# HK32F0301MxxC register map
Vendor: HKMicroChip Ltd.; Series: HK32F0301MxxC; File version: 0.9
CPU: CM0 r0p0, little endian, no MPU, no FPU, 3 interrupt priority bits
Registers are 32-bit, read-write, reset 0x0 unless marked. A register's access mark holds for its fields unless they carry their own. Offsets are from the block's base; [hi:lo] are bit positions; {n}, {i} and the like mark numbered series.

## TIM2
Base 0x40000000
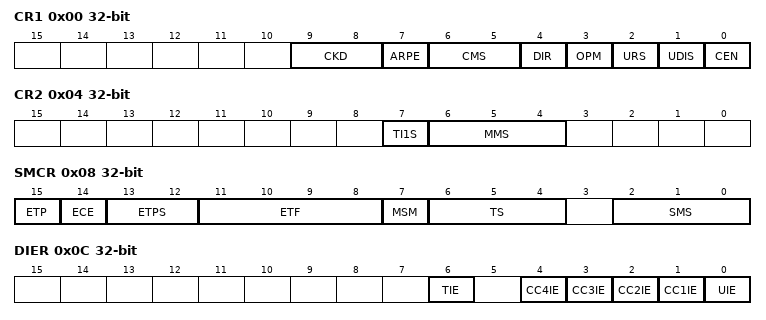
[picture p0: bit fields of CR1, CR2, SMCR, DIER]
0x00 CR1
  [9:8] CKD — Clock division
  [7] ARPE — Auto-reload preload enable
  [6:5] CMS — Center-aligned mode selection
  [4] DIR — Direction
  [3] OPM — One pulse mode
  [2] URS — Update request source
  [1] UDIS — Update disable
  [0] CEN — Counter enable
0x04 CR2
  [7] TI1S — TI1 selection
  [6:4] MMS — Master mode selection
0x08 SMCR
  [15] ETP — External trigger polarity
  [14] ECE — External clock enable
  [13:12] ETPS — External trigger prescaler
  [11:8] ETF — External trigger filter
  [7] MSM — Master/Slave mode
  [6:4] TS — Trigger selection
  [2:0] SMS — Slave mode selection
0x0C DIER
  [6] TIE — Trigger interrupt enable
  [n] CC{n}IE (n=1..4) — Capture/Compare {n} interrupt enable
  [0] UIE — Update interrupt enable
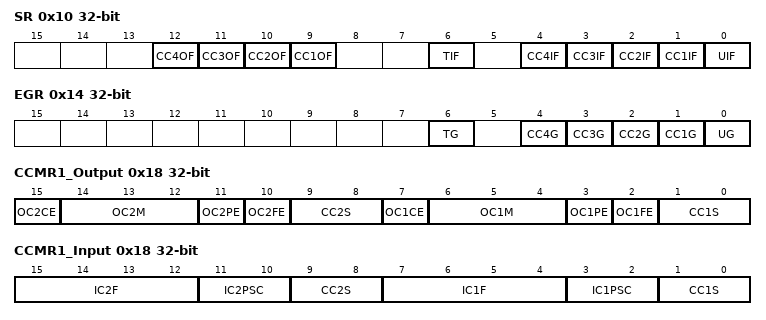
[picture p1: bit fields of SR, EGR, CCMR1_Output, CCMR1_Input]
0x10 SR
  [n+8] CC{n}OF (n=1..4) — Capture/Compare {n} overcapture flag
  [6] TIF — Trigger interrupt flag
  [n] CC{n}IF (n=1..4) — Capture/Compare {n} interrupt flag
  [0] UIF — Update interrupt flag
0x14 EGR wo
  [6] TG — Trigger generation
  [n] CC{n}G (n=1..4) — Capture/Compare {n} generation
  [0] UG — Update generation
0x18 CCMR1_Output
  [15] OC2CE — Output compare 2 clear enable
  [14:12] OC2M — Output compare 2 mode
  [11] OC2PE — Output compare 2 preload enable
  [10] OC2FE — Output compare 2 fast enable
  [9:8] CC2S — Capture/Compare 2 selection
  [7] OC1CE — Output compare 1 clear enable
  [6:4] OC1M — Output compare 1 mode
  [3] OC1PE — Output compare 1 preload enable
  [2] OC1FE — Output compare 1 fast enable
  [1:0] CC1S — Capture/Compare 1 selection
0x18 CCMR1_Input (alternate view of CCMR1_Output)
  [15:12] IC2F — Input capture 2 filter
  [11:10] IC2PSC — Input capture 2 prescaler
  [9:8] CC2S — Capture/compare 2 selection
  [7:4] IC1F — Input capture 1 filter
  [3:2] IC1PSC — Input capture 1 prescaler
  [1:0] CC1S — Capture/compare 1 selection
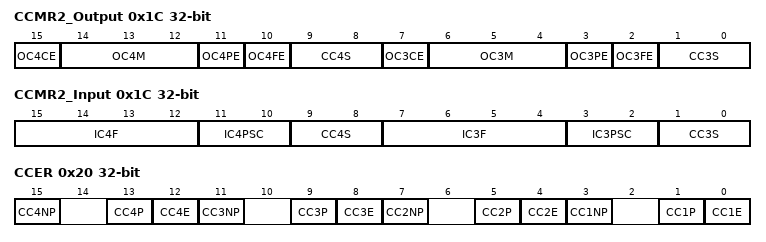
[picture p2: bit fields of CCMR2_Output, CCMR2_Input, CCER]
0x1C CCMR2_Output
  [15] OC4CE — Output compare 4 clear enable
  [14:12] OC4M — Output compare 4 mode
  [11] OC4PE — Output compare 4 preload enable
  [10] OC4FE — Output compare 4 fast enable
  [9:8] CC4S — Capture/Compare 4 selection
  [7] OC3CE — Output compare 3 clear enable
  [6:4] OC3M — Output compare 3 mode
  [3] OC3PE — Output compare 3 preload enable
  [2] OC3FE — Output compare 3 fast enable
  [1:0] CC3S — Capture/Compare 3 selection
0x1C CCMR2_Input (alternate view of CCMR2_Output)
  [15:12] IC4F — Input capture 4 filter
  [11:10] IC4PSC — Input capture 4 prescaler
  [9:8] CC4S — Capture/Compare 4 selection
  [7:4] IC3F — Input capture 3 filter
  [3:2] IC3PSC — Input capture 3 prescaler
  [1:0] CC3S — Capture/Compare 3 selection
0x20 CCER
  [4n-1] CC{n}NP (n=1..4) — Capture/Compare {n} output Polarity
  [4n-3] CC{n}P (n=1..4) — Capture/Compare {n} output Polarity
  [4n-4] CC{n}E (n=1..4) — Capture/Compare {n} output enable
0x24 CNT
  [15:0] CNT — Counter value
0x28 PSC
  [15:0] PSC — Prescaler value
0x2C ARR
  [15:0] ARR — Low auto-reload value
{0x30+4i} CCR{i} (i=1..4)
  [15:0] CCR{i} — Low Capture/Compare {i} value

## TIM6
Base 0x40001000
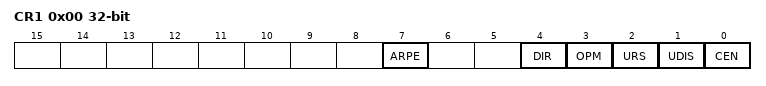
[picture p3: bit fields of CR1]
0x00 CR1
  [7] ARPE — Auto-reload preload enable
  [4] DIR — Direction
  [3] OPM — One pulse mode
  [2] URS — Update request source
  [1] UDIS — Update disable
  [0] CEN — Counter enable
0x04 CR2
  [6:4] MMS — Master mode selection
0x0C DIER
  [0] UIE — Update interrupt enable
0x10 SR
  [0] UIF — Update interrupt ﬂag
0x14 EGR wo
  [0] UG — Update generation
0x24 CNT
  [15:0] CNT — Counter value
0x28 PSC
  [15:0] PSC — Prescaler value
0x2C ARR reset 0xFFFF
  [15:0] ARR — Auto-reload value

## AWUT
Base 0x40007800
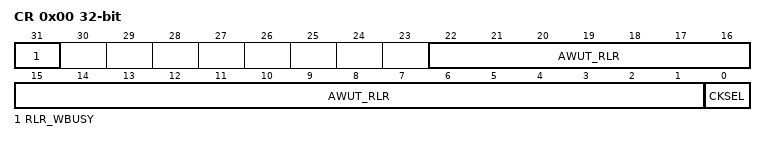
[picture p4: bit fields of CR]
0x00 CR access per field
  [31] RLR_WBUSY ro — Reload register write busy
  [22:1] AWUT_RLR rw — Automatic wakeup timer reload register
  [0] CKSEL rw — Automatic wakeup timer clock selection
0x04 SR ro
  [0] BUSY — Automatic wakeup timer busy
